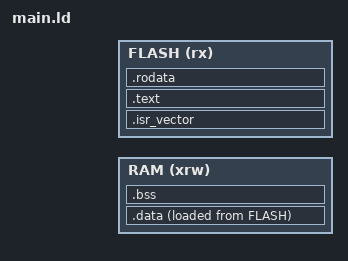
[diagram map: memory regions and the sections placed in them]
#include <generated/autoconf.h>

ENTRY(Reset_Handler)                    //固定使用Reset_Handler启动
_estack = ORIGIN(RAM) + LENGTH(RAM);

MEMORY
{
    RAM (xrw)       : ORIGIN = CONFIG_LD_RAM_START_ADDRESS    , LENGTH = CONFIG_LD_KERNEL_USE_RAM_SIZE * 1k
    FLASH (rx)      : ORIGIN = CONFIG_LD_FLASH_START_ADDRESS  , LENGTH = CONFIG_LD_KERNEL_USE_FLASH_SIZE * 1k
}


/* Define output sections */
SECTIONS
{
  /* The startup code goes first into FLASH */
  .isr_vector :
  {
    . = ALIGN(4);
    KEEP(*(.isr_vector)) /* Startup code */
    . = ALIGN(4);
  } >FLASH

  /* The program code and other data goes into FLASH */
  .text :
  {
    . = ALIGN(4);
    *(.text)           /* .text sections (code) */
    *(.text*)          /* .text* sections (code) */
    *(.glue_7)         /* glue arm to thumb code */
    *(.glue_7t)        /* glue thumb to arm code */
    *(.eh_frame)

    KEEP (*(.init))
    KEEP (*(.fini))

    . = ALIGN(4);
    _etext = .;        /* define a global symbols at end of code */
  } >FLASH

  /* Constant data goes into FLASH */
  .rodata :
  {
    . = ALIGN(4);
    *(.rodata)         /* .rodata sections (constants, strings, etc.) */
    *(.rodata*)        /* .rodata* sections (constants, strings, etc.) */
    . = ALIGN(4);
  } >FLASH

  /* used by the startup to initialize data */
  _sidata = LOADADDR(.data);

  /* Initialized data sections goes into RAM, load LMA copy after code */
  .data : 
  {
    . = ALIGN(4);
    _sdata = .;        /* create a global symbol at data start */
    *(.data)           /* .data sections */
    *(.data*)          /* .data* sections */

    . = ALIGN(4);
    _edata = .;        /* define a global symbol at data end */
  } >RAM AT> FLASH

 
  #include "sys.ld"
   
  /* Uninitialized data section */
  . = ALIGN(4);
  .bss :
  {
    /* This is used by the startup in order to initialize the .bss secion */
    _sbss = .;         /* define a global symbol at bss start */
    __bss_start__ = _sbss;
    *(.bss)
    *(.bss*)
    *(COMMON)

    . = ALIGN(4);
    _ebss = .;         /* define a global symbol at bss end */
    __bss_end__ = _ebss;
  } >RAM


}
